# ESP32-S31 register map
Vendor: ESPRESSIF SYSTEMS (SHANGHAI) CO., LTD.; Series: ESP32 S-Series; File version: 1
CPU: RV32IMAFC r0p0, little endian, no MPU, FPU, 0 interrupt priority bits
Address unit: 32 bits
Registers are 32-bit, read-write, reset 0x0 unless marked. A register's access mark holds for its fields unless they carry their own. Offsets are from the block's base; [hi:lo] are bit positions; {n}, {i} and the like mark numbered series.

## I2S0 — I2S (Inter-IC Sound) Controller 0
Base 0x20387000
Same registers: I2S1 0x20388000
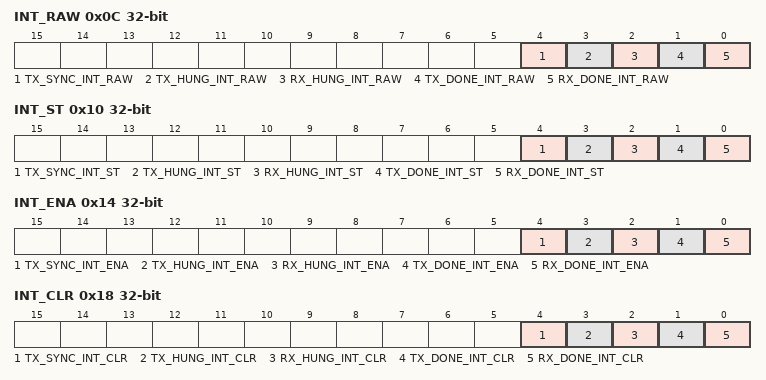
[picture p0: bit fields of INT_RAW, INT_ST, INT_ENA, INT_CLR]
0x0C INT_RAW ro — I2S interrupt raw register, valid in level.
  [4] TX_SYNC_INT_RAW — The raw interrupt status bit for the i2s_tx_sync_int interrupt
  [3] TX_HUNG_INT_RAW — The raw interrupt status bit for the i2s_tx_hung_int interrupt
  [2] RX_HUNG_INT_RAW — The raw interrupt status bit for the i2s_rx_hung_int interrupt
  [1] TX_DONE_INT_RAW — The raw interrupt status bit for the i2s_tx_done_int interrupt
  [0] RX_DONE_INT_RAW — The raw interrupt status bit for the i2s_rx_done_int interrupt
0x10 INT_ST ro — I2S interrupt status register.
  [4] TX_SYNC_INT_ST — The masked interrupt status bit for the i2s_tx_sync_int interrupt
  [3] TX_HUNG_INT_ST — The masked interrupt status bit for the i2s_tx_hung_int interrupt
  [2] RX_HUNG_INT_ST — The masked interrupt status bit for the i2s_rx_hung_int interrupt
  [1] TX_DONE_INT_ST — The masked interrupt status bit for the i2s_tx_done_int interrupt
  [0] RX_DONE_INT_ST — The masked interrupt status bit for the i2s_rx_done_int interrupt
0x14 INT_ENA — I2S interrupt enable register.
  [4] TX_SYNC_INT_ENA — The interrupt enable bit for the i2s_tx_sync_int interrupt
  [3] TX_HUNG_INT_ENA — The interrupt enable bit for the i2s_tx_hung_int interrupt
  [2] RX_HUNG_INT_ENA — The interrupt enable bit for the i2s_rx_hung_int interrupt
  [1] TX_DONE_INT_ENA — The interrupt enable bit for the i2s_tx_done_int interrupt
  [0] RX_DONE_INT_ENA — The interrupt enable bit for the i2s_rx_done_int interrupt
0x18 INT_CLR wo — I2S interrupt clear register.
  [4] TX_SYNC_INT_CLR — Set this bit to clear the i2s_tx_sync_int interrupt
  [3] TX_HUNG_INT_CLR — Set this bit to clear the i2s_tx_hung_int interrupt
  [2] RX_HUNG_INT_CLR — Set this bit to clear the i2s_rx_hung_int interrupt
  [1] TX_DONE_INT_CLR — Set this bit to clear the i2s_tx_done_int interrupt
  [0] RX_DONE_INT_CLR — Set this bit to clear the i2s_rx_done_int interrupt
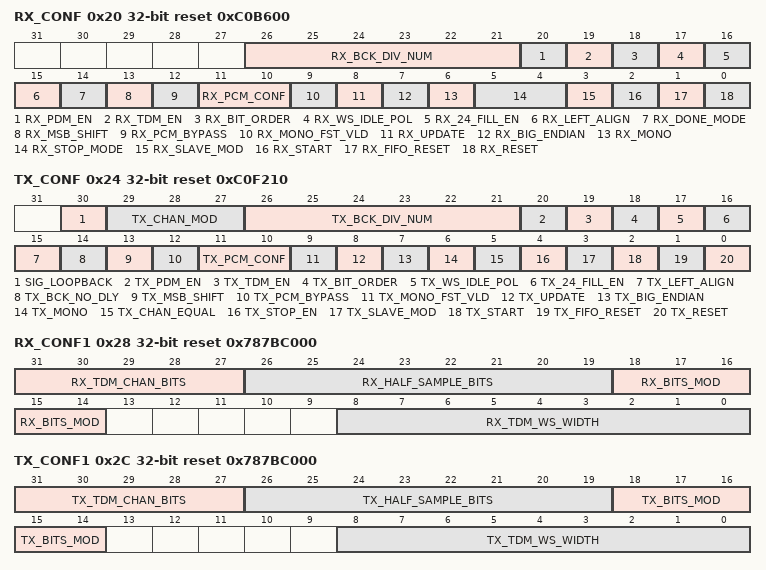
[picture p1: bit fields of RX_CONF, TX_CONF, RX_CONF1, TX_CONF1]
0x20 RX_CONF access per field reset 0xC0B600 — I2S RX configure register
  [26:21] RX_BCK_DIV_NUM rw — Bit clock configuration bits in receiver mode.
  [20] RX_PDM_EN rw — 1: Enable I2S PDM Rx mode . 0: Disable.
  [19] RX_TDM_EN rw — 1: Enable I2S TDM Rx mode . 0: Disable.
  [18] RX_BIT_ORDER rw — I2S Rx bit endian. 1:small endian, the LSB is received first. 0:big endian, the MSB is received first.
  [17] RX_WS_IDLE_POL rw — 0: WS should be 0 when receiving left channel data, and WS is 1in right channel. 1: WS should be 1 when receiving left channel data, and WS is 0in right channel.
  [16] RX_24_FILL_EN rw — 1: store 24 channel bits to 32 bits. 0:store 24 channel bits to 24 bits.
  [15] RX_LEFT_ALIGN rw — 1: I2S RX left alignment mode. 0: I2S RX right alignment mode.
  [14] RX_DONE_MODE rw — 1: I2S trigger rx_done when in_suc_eof is 1. 0: I2S trigger rx_done when RX FIFO is full.
  [13] RX_MSB_SHIFT rw — Set this bit to enable receiver in Phillips standard mode
  [12] RX_PCM_BYPASS rw — Set this bit to bypass Compress/Decompress module for received data.
  [11:10] RX_PCM_CONF rw — I2S RX compress/decompress configuration bit. & 0 (atol): A-Law decompress, 1 (ltoa) : A-Law compress, 2 (utol) : u-Law decompress, 3 (ltou) : u-Law compress. &
  [9] RX_MONO_FST_VLD rw — 1: The first channel data value is valid in I2S RX mono mode. 0: The second channel data value is valid in I2S RX mono mode.
  [8] RX_UPDATE rw — Set 1 to update I2S RX registers from APB clock domain to I2S RX clock domain. This bit will be cleared by hardware after update register done.
  [7] RX_BIG_ENDIAN rw — I2S Rx byte endian, 1: low addr value to high addr. 0: low addr with low addr value.
  [6] RX_MONO rw — Set this bit to enable receiver in mono mode
  [5:4] RX_STOP_MODE rw — 0 : I2S Rx only stop when reg_rx_start is cleared. 1: Stop when reg_rx_start is 0 or in_suc_eof is 1. 2: Stop I2S RX when reg_rx_start is 0 or RX FIFO is full.
  [3] RX_SLAVE_MOD rw — Set this bit to enable slave receiver mode
  [2] RX_START rw — Set this bit to start receiving data
  [1] RX_FIFO_RESET wo — Set this bit to reset Rx AFIFO
  [0] RX_RESET wo — Set this bit to reset receiver
0x24 TX_CONF access per field reset 0xC0F210 — I2S TX configure register
  [30] SIG_LOOPBACK rw — Enable signal loop back mode with transmitter module and receiver module sharing the same WS and BCK signals.
  [29:27] TX_CHAN_MOD rw — I2S transmitter channel mode configuration bits.
  [26:21] TX_BCK_DIV_NUM rw — Bit clock configuration bits in transmitter mode.
  [20] TX_PDM_EN rw — 1: Enable I2S PDM Tx mode . 0: Disable.
  [19] TX_TDM_EN rw — 1: Enable I2S TDM Tx mode . 0: Disable.
  [18] TX_BIT_ORDER rw — I2S Tx bit endian. 1:small endian, the LSB is sent first. 0:big endian, the MSB is sent first.
  [17] TX_WS_IDLE_POL rw — 0: WS should be 0 when sending left channel data, and WS is 1in right channel. 1: WS should be 1 when sending left channel data, and WS is 0in right channel.
  [16] TX_24_FILL_EN rw — 1: Sent 32 bits in 24 channel bits mode. 0: Sent 24 bits in 24 channel bits mode
  [15] TX_LEFT_ALIGN rw — 1: I2S TX left alignment mode. 0: I2S TX right alignment mode.
  [14] TX_BCK_NO_DLY rw — 1: BCK is not delayed to generate pos/neg edge in master mode. 0: BCK is delayed to generate pos/neg edge in master mode.
  [13] TX_MSB_SHIFT rw — Set this bit to enable transmitter in Phillips standard mode
  [12] TX_PCM_BYPASS rw — Set this bit to bypass Compress/Decompress module for transmitted data.
  [11:10] TX_PCM_CONF rw — I2S TX compress/decompress configuration bit. & 0 (atol): A-Law decompress, 1 (ltoa) : A-Law compress, 2 (utol) : u-Law decompress, 3 (ltou) : u-Law compress. &
  [9] TX_MONO_FST_VLD rw — 1: The first channel data value is valid in I2S TX mono mode. 0: The second channel data value is valid in I2S TX mono mode.
  [8] TX_UPDATE rw — Set 1 to update I2S TX registers from APB clock domain to I2S TX clock domain. This bit will be cleared by hardware after update register done.
  [7] TX_BIG_ENDIAN rw — I2S Tx byte endian, 1: low addr value to high addr. 0: low addr with low addr value.
  [6] TX_MONO rw — Set this bit to enable transmitter in mono mode
  [5] TX_CHAN_EQUAL rw — 1: The value of Left channel data is equal to the value of right channel data in I2S TX mono mode or TDM channel select mode. 0: The invalid channel data is reg_i2s_single_data in I2S TX mono mode or TDM channel select mode.
  [4] TX_STOP_EN rw — Set this bit to stop disable output BCK signal and WS signal when tx FIFO is emtpy
  [3] TX_SLAVE_MOD rw — Set this bit to enable slave transmitter mode
  [2] TX_START rw — Set this bit to start transmitting data
  [1] TX_FIFO_RESET wo — Set this bit to reset Tx AFIFO
  [0] TX_RESET wo — Set this bit to reset transmitter
0x28 RX_CONF1 reset 0x787BC000 — I2S RX configure register 1
  [31:27] RX_TDM_CHAN_BITS — The Rx bit number for each channel minus 1in TDM mode.
  [26:19] RX_HALF_SAMPLE_BITS — I2S Rx half sample bits -1.
  [18:14] RX_BITS_MOD — Set the bits to configure the valid data bit length of I2S receiver channel. 7: all the valid channel data is in 8-bit-mode. 15: all the valid channel data is in 16-bit-mode. 23: all the valid channel data is in 24-bit-mode. 31:all the valid channel data is in 32-bit-mode.
  [8:0] RX_TDM_WS_WIDTH — The width of rx_ws_out at idle level in TDM mode is (I2S_RX_TDM_WS_WIDTH[8:0] +1) * T_bck
0x2C TX_CONF1 reset 0x787BC000 — I2S TX configure register 1
  [31:27] TX_TDM_CHAN_BITS — The Tx bit number for each channel minus 1in TDM mode.
  [26:19] TX_HALF_SAMPLE_BITS — I2S Tx half sample bits -1.
  [18:14] TX_BITS_MOD — Set the bits to configure the valid data bit length of I2S transmitter channel. 7: all the valid channel data is in 8-bit-mode. 15: all the valid channel data is in 16-bit-mode. 23: all the valid channel data is in 24-bit-mode. 31:all the valid channel data is in 32-bit-mode.
  [8:0] TX_TDM_WS_WIDTH — The width of tx_ws_out at idle level in TDM mode is (I2S_TX_TDM_WS_WIDTH[8:0] +1) * T_bck
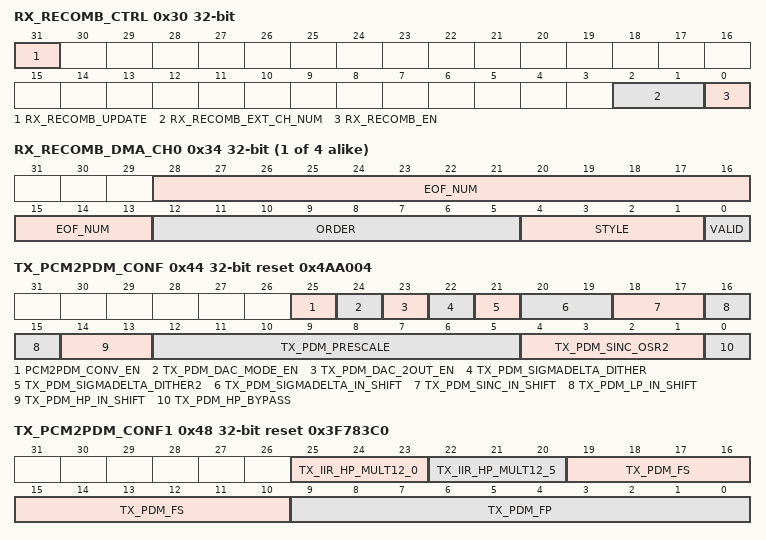
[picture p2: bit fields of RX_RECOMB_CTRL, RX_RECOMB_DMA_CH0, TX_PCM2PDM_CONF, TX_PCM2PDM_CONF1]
0x30 RX_RECOMB_CTRL access per field — I2S RX configure register 1
  [31] RX_RECOMB_UPDATE wo — Set this bit to update i2s data recombination configuration, must be performed after changing the config of any recombined-dma-channel.
  [2:1] RX_RECOMB_EXT_CH_NUM rw — The channel number that i2s will extract the data into.
  [0] RX_RECOMB_EN rw — Set this bit to enable i2s rx data recombination.
{0x34+4i} RX_RECOMB_DMA_CH{i} (i=0..3) — I2S RX recombined-dma-channel configuration register
  [28:13] EOF_NUM — Set this field to set the receive eof byte length of the recombined-dma-channel.
  [12:5] ORDER — Set this field to set the recombined-dma-channel order. If choose to use the order ch3 -> ch1, the order should be: 8'd7 = {2'd0,2'd0,2'd1,2'd3}.
  [4:1] STYLE — Set this field to set the recombined-dma-channel style. If choose to use i2s extracted ch 1&3 in 4 channels, the style should be: 6'b1010.
  [0] VALID — Set this bit to enable the adc-dma-channel.
0x44 TX_PCM2PDM_CONF reset 0x4AA004 — I2S TX PCM2PDM configuration register
  [25] PCM2PDM_CONV_EN — I2S TX PDM Converter enable
  [24] TX_PDM_DAC_MODE_EN — I2S TX PDM dac 2channel enable
  [23] TX_PDM_DAC_2OUT_EN — I2S TX PDM dac mode enable
  [22] TX_PDM_SIGMADELTA_DITHER — I2S TX PDM sigmadelta dither value
  [21] TX_PDM_SIGMADELTA_DITHER2 — I2S TX PDM sigmadelta dither2 value
  [20:19] TX_PDM_SIGMADELTA_IN_SHIFT — I2S TX PDM sigmadelta scale shift number: 0:/2 , 1:x1 , 2:x2 , 3: x4
  [18:17] TX_PDM_SINC_IN_SHIFT — I2S TX PDM sigmadelta scale shift number: 0:/2 , 1:x1 , 2:x2 , 3: x4
  [16:15] TX_PDM_LP_IN_SHIFT — I2S TX PDM sigmadelta scale shift number: 0:/2 , 1:x1 , 2:x2 , 3: x4
  [14:13] TX_PDM_HP_IN_SHIFT — I2S TX PDM sigmadelta scale shift number: 0:/2 , 1:x1 , 2:x2 , 3: x4
  [12:5] TX_PDM_PRESCALE — I2S TX PDM prescale for sigmadelta
  [4:1] TX_PDM_SINC_OSR2 — I2S TX PDM OSR2 value
  [0] TX_PDM_HP_BYPASS — I2S TX PDM bypass hp filter or not. The option has been removed.
0x48 TX_PCM2PDM_CONF1 reset 0x3F783C0 — I2S TX PCM2PDM configuration register
  [25:23] TX_IIR_HP_MULT12_0 — The fourth parameter of PDM TX IIR_HP filter stage 1 is (504 + I2S_TX_IIR_HP_MULT12_0[2:0])
  [22:20] TX_IIR_HP_MULT12_5 — The fourth parameter of PDM TX IIR_HP filter stage 2 is (504 + I2S_TX_IIR_HP_MULT12_5[2:0])
  [19:10] TX_PDM_FS — I2S TX PDM Fs
  [9:0] TX_PDM_FP — I2S TX PDM Fp
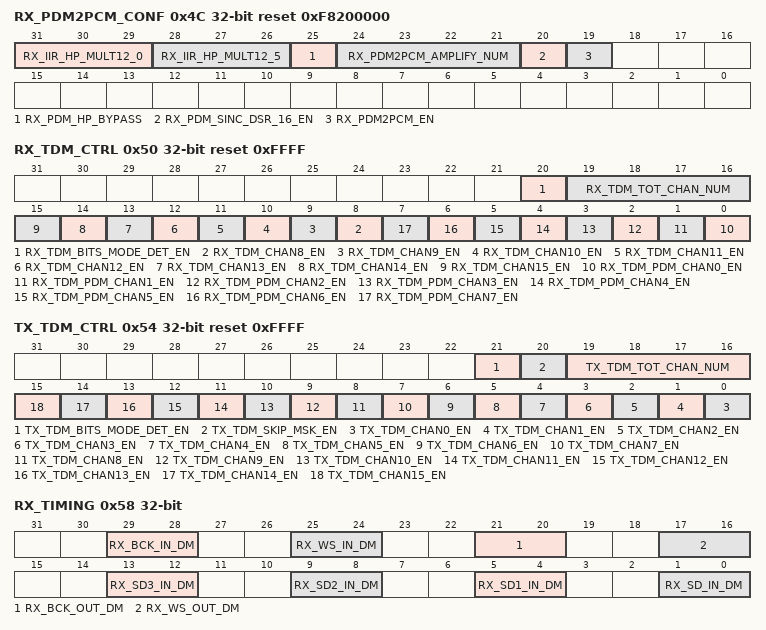
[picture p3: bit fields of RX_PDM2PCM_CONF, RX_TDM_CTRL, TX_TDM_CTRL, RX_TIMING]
0x4C RX_PDM2PCM_CONF reset 0xF8200000 — I2S RX configure register
  [31:29] RX_IIR_HP_MULT12_0 — The fourth parameter of PDM RX IIR_HP filter stage 1 is (504 + LP_I2S_RX_IIR_HP_MULT12_0[2:0])
  [28:26] RX_IIR_HP_MULT12_5 — The fourth parameter of PDM RX IIR_HP filter stage 2 is (504 + LP_I2S_RX_IIR_HP_MULT12_5[2:0])
  [25] RX_PDM_HP_BYPASS — I2S PDM RX bypass hp filter or not.
  [24:21] RX_PDM2PCM_AMPLIFY_NUM — Configure PDM RX amplify number.
  [20] RX_PDM_SINC_DSR_16_EN — Configure the down sampling rate of PDM RX filter group1 module. 1: The down sampling rate is 128. 0: down sampling rate is 64.
  [19] RX_PDM2PCM_EN — 1: Enable PDM2PCM RX mode. 0: DIsable.
0x50 RX_TDM_CTRL reset 0xFFFF — I2S TX TDM mode control register
  [20] RX_TDM_BITS_MODE_DET_EN — 1: Auto detect bit mode in tdm slave mode. 0: Disable.
  [19:16] RX_TDM_TOT_CHAN_NUM — The total channel number of I2S TX TDM mode.
  [n] RX_TDM_CHAN{n}_EN (n=8..15) — 1: Enable the valid data input of I2S RX TDM channel {n}. 0: Disable, just input 0 in this channel.
  [n] RX_TDM_PDM_CHAN{n}_EN (n=0..7) — 1: Enable the valid data input of I2S RX TDM or PDM channel {n}. 0: Disable, just input 0 in this channel.
0x54 TX_TDM_CTRL reset 0xFFFF — I2S TX TDM mode control register
  [21] TX_TDM_BITS_MODE_DET_EN — 1: Auto detect bit mode in tdm slave mode. 0: Disable.
  [20] TX_TDM_SKIP_MSK_EN — When DMA TX buffer stores the data of (REG_TX_TDM_TOT_CHAN_NUM + 1) channels, and only the data of the enabled channels is sent, then this bit should be set. Clear it when all the data stored in DMA TX buffer is for enabled channels.
  [19:16] TX_TDM_TOT_CHAN_NUM — The total channel number of I2S TX TDM mode.
  [n] TX_TDM_CHAN{n}_EN (n=0..15) — 1: Enable the valid data output of I2S TX TDM channel {n}. 0: Disable, just output 0 in this channel.
0x58 RX_TIMING — I2S RX timing control register
  [29:28] RX_BCK_IN_DM — The delay mode of I2S Rx BCK input signal. 0: bypass. 1: delay by pos edge. 2: delay by neg edge. 3: not used.
  [25:24] RX_WS_IN_DM — The delay mode of I2S Rx WS input signal. 0: bypass. 1: delay by pos edge. 2: delay by neg edge. 3: not used.
  [21:20] RX_BCK_OUT_DM — The delay mode of I2S Rx BCK output signal. 0: bypass. 1: delay by pos edge. 2: delay by neg edge. 3: not used.
  [17:16] RX_WS_OUT_DM — The delay mode of I2S Rx WS output signal. 0: bypass. 1: delay by pos edge. 2: delay by neg edge. 3: not used.
  [13:12] RX_SD3_IN_DM — The delay mode of I2S Rx SD3 input signal. 0: bypass. 1: delay by pos edge. 2: delay by neg edge. 3: not used.
  [9:8] RX_SD2_IN_DM — The delay mode of I2S Rx SD2 input signal. 0: bypass. 1: delay by pos edge. 2: delay by neg edge. 3: not used.
  [5:4] RX_SD1_IN_DM — The delay mode of I2S Rx SD1 input signal. 0: bypass. 1: delay by pos edge. 2: delay by neg edge. 3: not used.
  [1:0] RX_SD_IN_DM — The delay mode of I2S Rx SD input signal. 0: bypass. 1: delay by pos edge. 2: delay by neg edge. 3: not used.
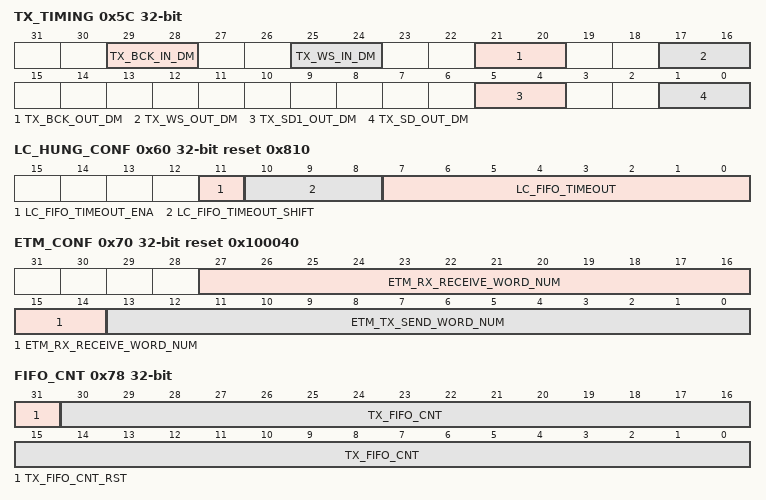
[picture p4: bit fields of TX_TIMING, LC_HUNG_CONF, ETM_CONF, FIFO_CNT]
0x5C TX_TIMING — I2S TX timing control register
  [29:28] TX_BCK_IN_DM — The delay mode of I2S TX BCK input signal. 0: bypass. 1: delay by pos edge. 2: delay by neg edge. 3: not used.
  [25:24] TX_WS_IN_DM — The delay mode of I2S TX WS input signal. 0: bypass. 1: delay by pos edge. 2: delay by neg edge. 3: not used.
  [21:20] TX_BCK_OUT_DM — The delay mode of I2S TX BCK output signal. 0: bypass. 1: delay by pos edge. 2: delay by neg edge. 3: not used.
  [17:16] TX_WS_OUT_DM — The delay mode of I2S TX WS output signal. 0: bypass. 1: delay by pos edge. 2: delay by neg edge. 3: not used.
  [5:4] TX_SD1_OUT_DM — The delay mode of I2S TX SD1 output signal. 0: bypass. 1: delay by pos edge. 2: delay by neg edge. 3: not used.
  [1:0] TX_SD_OUT_DM — The delay mode of I2S TX SD output signal. 0: bypass. 1: delay by pos edge. 2: delay by neg edge. 3: not used.
0x60 LC_HUNG_CONF reset 0x810 — I2S HUNG configure register.
  [11] LC_FIFO_TIMEOUT_ENA — The enable bit for FIFO timeout
  [10:8] LC_FIFO_TIMEOUT_SHIFT — The bits are used to scale tick counter threshold. The tick counter is reset when counter value >= 88000/2^i2s_lc_fifo_timeout_shift
  [7:0] LC_FIFO_TIMEOUT — the i2s_tx_hung_int interrupt or the i2s_rx_hung_int interrupt will be triggered when fifo hung counter is equal to this value
0x64 RXEOF_NUM reset 0x40 — I2S RX data number control register.
  [15:0] RX_EOF_NUM — The receive data bit length is (I2S_RX_BITS_MOD[4:0] + 1) * (REG_RX_EOF_NUM[15:0]) . It will trigger in_suc_eof interrupt in the configured DMA RX channel.
0x68 CONF_SIGLE_DATA — I2S signal data register
  [31:0] SINGLE_DATA — The configured constant channel data to be sent out.
0x6C STATE ro reset 0x1 — I2S TX status register
  [0] TX_IDLE — 1: i2s_tx is idle state. 0: i2s_tx is working.
0x70 ETM_CONF reset 0x100040 — I2S ETM configure register
  [27:14] ETM_RX_RECEIVE_WORD_NUM — I2S ETM receive x words event. When receiving word number of reg_etm_rx_receive_word_num[13:0], i2s will trigger an etm event.
  [13:0] ETM_TX_SEND_WORD_NUM — I2S ETM send x words event. When sending word number of reg_etm_tx_send_word_num[13:0], i2s will trigger an etm event.
0x74 IDEAL_CNT — I2S sync counter register
  [30:0] TX_IDEAL_CNT — tx fifo counter ideal value.
0x78 FIFO_CNT access per field — I2S sync counter register
  [31] TX_FIFO_CNT_RST wo — Set this bit to reset tx fifo counter.
  [30:0] TX_FIFO_CNT ro — tx fifo counter value.
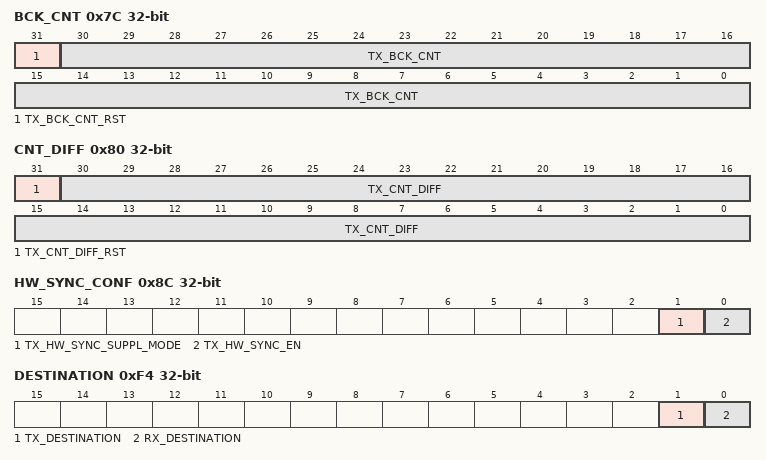
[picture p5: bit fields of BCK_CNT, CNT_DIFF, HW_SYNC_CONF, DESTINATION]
0x7C BCK_CNT access per field — I2S sync counter register
  [31] TX_BCK_CNT_RST wo — Set this bit to reset tx bck counter.
  [30:0] TX_BCK_CNT ro — tx bck counter value.
0x80 CNT_DIFF access per field — I2S sync counter register
  [31] TX_CNT_DIFF_RST wo — Set this bit to reset fifo counter difference.
  [30:0] TX_CNT_DIFF ro — tx bck counter value.
0x84 SYNC_SW_THRES — I2S sync counter register
  [30:0] TX_CNT_DIFF_SW_THRES — tx fifo counter difference software threshold value, when difference larger than this threshold, interrupt will occur and hardware sync will not be executed.
0x88 SYNC_HW_THRES — I2S sync counter register
  [30:0] TX_CNT_DIFF_HW_THRES — tx fifo counter difference hardware threshold value, which means that only when difference larger than this threshold will hardware start hardware sync.
0x8C HW_SYNC_CONF — I2S TX hardware sync function configuration register
  [1] TX_HW_SYNC_SUPPL_MODE — Configure the i2s tx hardware sync supplementation mode. 1: Supplement the data configured in I2S_TX_HW_SYNC_SUPPL_DATA[31:0]. 0: Supplement the last data.
  [0] TX_HW_SYNC_EN — Configure whether enable i2s tx hardware sync function. 1: Enable. 0: Disable
0x90 HW_SYNC_DATA — I2S TX hardware sync function configuration register
  [31:0] TX_HW_SYNC_SUPPL_DATA — Configure the i2s tx hardware sync supplementation data when I2S_TX_HW_SYNC_SUPPL_MODE is 1.
0xF4 DESTINATION — I2S TX status register
  [1] TX_DESTINATION — Set this bit to configure the data destination of i2s tx. 1: ble. 0: gdma.
  [0] RX_DESTINATION — Set this bit to configure the data destination of i2s rx. 1: ble. 0: gdma.
0xF8 CLK_GATE — Clock gate register
  [0] CLK_EN — set this bit to enable clock gate
0xFC DATE reset 0x2504030 — Version control register
  [27:0] DATE — I2S version control register
